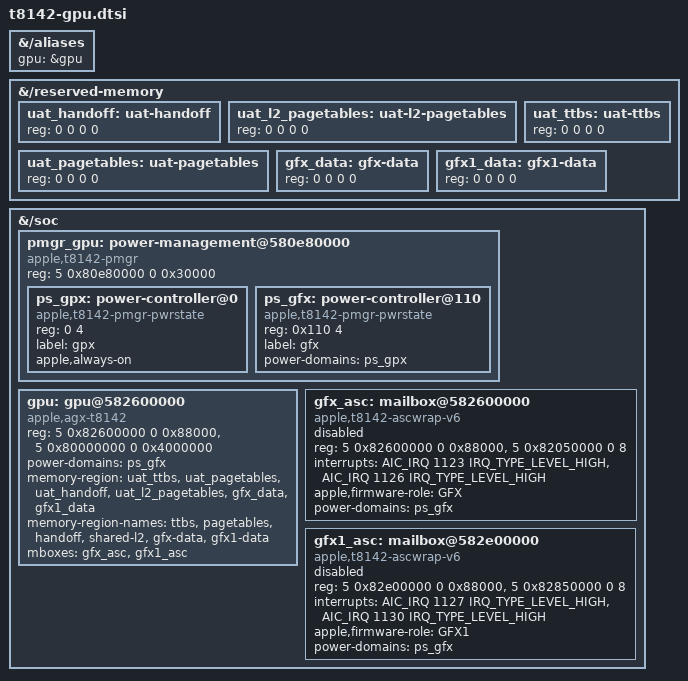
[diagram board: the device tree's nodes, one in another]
// SPDX-License-Identifier: GPL-2.0+ OR MIT
/* M5 resources measured from Mac17,3's ADT. The current Asahi M5 path is
 * identification-only; these nodes do not qualify firmware or rendering.
 */
&{/aliases} {
	gpu = &gpu;
};

&{/reserved-memory} {
	uat_handoff: uat-handoff { reg = <0 0 0 0>; };
	uat_l2_pagetables: uat-l2-pagetables { reg = <0 0 0 0>; };
	uat_pagetables: uat-pagetables { reg = <0 0 0 0>; };
	uat_ttbs: uat-ttbs { reg = <0 0 0 0>; };
	gfx_data: gfx-data { reg = <0 0 0 0>; };
	gfx1_data: gfx1-data { reg = <0 0 0 0>; };
};

&{/soc} {
	/* ps-groups[2].reg=48, device514 offset0x110. This is a
	 * separate PMGR register bank from the AVE group0 controller. */
	pmgr_gpu: power-management@580e80000 {
		compatible = "apple,t8142-pmgr", "apple,pmgr", "syscon", "simple-mfd";
		reg = <5 0x80e80000 0 0x30000>;
		#address-cells = <1>;
		#size-cells = <1>;
		ps_gpx: power-controller@0 {
			compatible = "apple,t8142-pmgr-pwrstate", "apple,pmgr-pwrstate";
			reg = <0 4>;
			#power-domain-cells = <0>;
			#reset-cells = <0>;
			label = "gpx";
			/* Diagnostic v9 observed GPX refuse power-gating after the
			 * identity probe. Preserve it until its shutdown is traced. */
			apple,always-on;
		};
		ps_gfx: power-controller@110 {
			compatible = "apple,t8142-pmgr-pwrstate", "apple,pmgr-pwrstate";
			reg = <0x110 4>;
			#power-domain-cells = <0>;
			#reset-cells = <0>;
			label = "gfx";
			power-domains = <&ps_gpx>;
		};
	};

	gpu: gpu@582600000 {
		compatible = "apple,agx-t8142";
		reg = <5 0x82600000 0 0x88000>, <5 0x80000000 0 0x4000000>;
		reg-names = "asc", "sgx";
		power-domains = <&ps_gfx>;
		memory-region = <&uat_ttbs>, <&uat_pagetables>, <&uat_handoff>,
				<&uat_l2_pagetables>, <&gfx_data>, <&gfx1_data>;
		memory-region-names = "ttbs", "pagetables", "handoff", "shared-l2",
				      "gfx-data", "gfx1-data";
		mboxes = <&gfx_asc>, <&gfx1_asc>;
	};

	/* The role providers remain disabled until M5 firmware admission and
	 * runtime ownership are implemented. Do not select the Neo runtime. */
	gfx_asc: mailbox@582600000 {
		compatible = "apple,t8142-ascwrap-v6";
		reg = <5 0x82600000 0 0x88000>, <5 0x82050000 0 8>;
		reg-names = "wrapper", "iop-vbar";
		interrupts = <AIC_IRQ 1123 IRQ_TYPE_LEVEL_HIGH>, <AIC_IRQ 1126 IRQ_TYPE_LEVEL_HIGH>;
		interrupt-names = "send-empty", "recv-not-empty";
		apple,firmware-role = "GFX";
		power-domains = <&ps_gfx>;
		#mbox-cells = <0>;
		status = "disabled";
	};
	gfx1_asc: mailbox@582e00000 {
		compatible = "apple,t8142-ascwrap-v6";
		reg = <5 0x82e00000 0 0x88000>, <5 0x82850000 0 8>;
		reg-names = "wrapper", "iop-vbar";
		interrupts = <AIC_IRQ 1127 IRQ_TYPE_LEVEL_HIGH>, <AIC_IRQ 1130 IRQ_TYPE_LEVEL_HIGH>;
		interrupt-names = "send-empty", "recv-not-empty";
		apple,firmware-role = "GFX1";
		power-domains = <&ps_gfx>;
		#mbox-cells = <0>;
		status = "disabled";
	};
};
